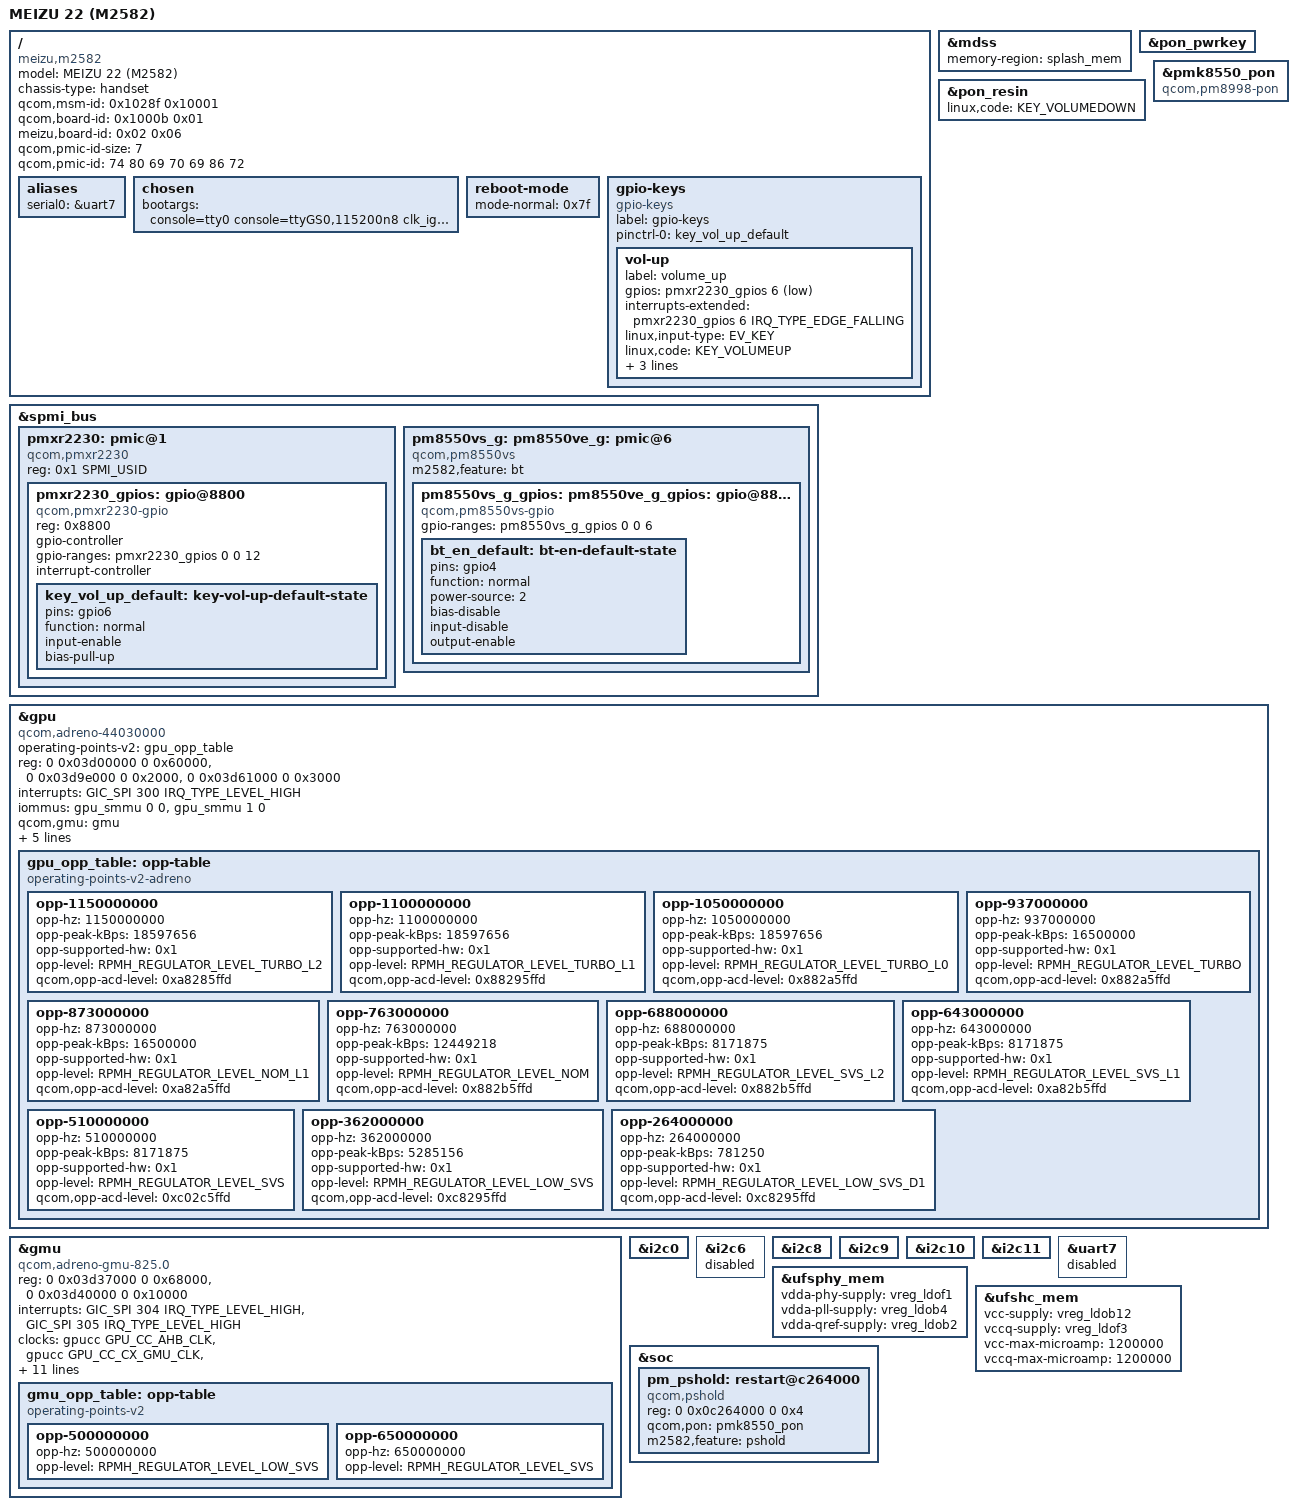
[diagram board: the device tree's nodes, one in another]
// SPDX-License-Identifier: BSD-3-Clause
/dts-v1/;
#include <dt-bindings/input/linux-event-codes.h>
#include "tuna.dtsi"
#include "meizu-m2582-memory.dtsi"
#include "meizu-m2582-power.dtsi"
#include "meizu-m2582-regulators.dtsi"
#include "tuna-display.dtsi"
#include "tuna-usb.dtsi"
#include "tuna-i2c.dtsi"
#include "meizu-m2582-i2c.dtsi"
#include "meizu-m2582-touch.dtsi"
#include "meizu-m2582-wcn-power.dtsi"
#include "meizu-m2582-bt.dtsi"
#include "meizu-m2582-adsp.dtsi"
#include "meizu-m2582-pcie.dtsi"
#include "meizu-m2582-dp.dtsi"
#include "meizu-m2582-audio.dtsi"

&mdss {
	memory-region = <&splash_mem>;
};

/*
 * The PMK8550 sits on the SPMI bus declared in tuna.dtsi. This brings in the
 * PMIC node, its SDAM2 (whose restart-reason field the bootloader reads to pick
 * between Linux and fastboot) and the nvmem-reboot-mode node that writes it.
 *
 * It also adds the PMIC's PON, RTC, GPIO and PWM blocks. PON and PWM are
 * status = "disabled" upstream, and none of the four needs an RPMh regulator,
 * so this deliberately stays clear of the RPMh path that hangs this board.
 */
#include "pmk8550.dtsi"
/* 需要 &pmk8550 标签，必须放在 pmk8550.dtsi 之后 */
#include "meizu-m2582-vadc.dtsi"
/* PMIC GPIO and thermal nodes are separate from the RPMh regulator providers. */
#include "sm8750-pmics.dtsi"
#include "pmd8028.dtsi"
#include "meizu-m2582-amoled.dtsi"
/* 需要 &spmi_bus 标签，必须放在 sm8750-pmics.dtsi 之后 */
#include "meizu-m2582-thermal.dtsi"

/ {
	/*
	 * ASCII only, deliberately: the em dash this used to contain is legal in
	 * a device tree and dtc takes it, but dtschema's decoder rejects the DTB
	 * before any validation runs ("Could not decode node / property model
	 * ... UnicodeDecodeError: 'ascii' codec can't decode byte 0xe2"), so
	 * every make dtbs_check run on this board died at the root node and
	 * looked like a tooling problem rather than a board one.
	 */
	model = "MEIZU 22 (M2582)";
	compatible = "meizu,m2582", "qcom,tuna";
	chassis-type = "handset";
	/* Live socinfo: SM8735 1.1, foundry 1, QRD platform 1.0. */
	qcom,msm-id = <0x1028f 0x10001>;
	qcom,board-id = <0x1000b 0x01>;
	/* ro.boot.proj_version=2, ro.boot.hw_version=6. */
	meizu,board-id = <0x02 0x06>;
	/* Live SMEM PMIC model order, no invented unused slots/revisions. */
	qcom,pmic-id-size = <7>;
	qcom,pmic-id = <74 80 69 70 69 86 72>;
	aliases { serial0 = &uart7; };
	chosen {
		bootargs = "console=tty0 console=ttyGS0,115200n8 clk_ignore_unused pd_ignore_unused cpuidle.off=1 rdinit=/init";
	};
};
/*
 * A nonzero normal reboot reason clears a retained fastboot request.
 * The seven-bit SDAM field uses 0x7f, which ABL treats as a normal boot.
 */
/ {
	reboot-mode {
		mode-normal = <0x7f>;
	};
};

/* PMK8550 PON inputs provide KEY_POWER and volume-down events. */
&pon_pwrkey {
	status = "okay";
};

&pon_resin {
	status = "okay";
	/*
	 * pmk8550.dtsi leaves the key code unset, so the driver's default is used
	 * and volume-down reports KEY_POWER, exactly like the power button. The
	 * factory tree gives it 114 (KEY_VOLUMEDOWN); measured on the board, the
	 * key does deliver events, it just delivered the wrong code.
	 */
	linux,code = <KEY_VOLUMEDOWN>;
};

/* Volume-up is active-low on PMXR2230 GPIO6; the other buttons use PMK8550 PON. */
&spmi_bus {
	pmxr2230: pmic@1 {
		compatible = "qcom,pmxr2230", "qcom,spmi-pmic";
		reg = <0x1 SPMI_USID>;
		#address-cells = <1>;
		#size-cells = <0>;

		pmxr2230_gpios: gpio@8800 {
			compatible = "qcom,pmxr2230-gpio", "qcom,spmi-gpio";
			reg = <0x8800>;
			gpio-controller;
			gpio-ranges = <&pmxr2230_gpios 0 0 12>;
			#gpio-cells = <2>;
			interrupt-controller;
			#interrupt-cells = <2>;
		};
	};
};

&pmxr2230_gpios {
	/*
	 * Measured on the board: `in high normal vin-1 pull-up 30uA`, which is
	 * exactly what the button needs -- idle high, pulled low when pressed,
	 * matching GPIO_ACTIVE_LOW below.
	 *
	 * The factory tree also sets power-source = <1> on this pad. It is left
	 * out: the level reads correctly on the default supply, and adding it
	 * changed nothing measurable.
	 */
	key_vol_up_default: key-vol-up-default-state {
		pins = "gpio6";
		function = "normal";
		input-enable;
		bias-pull-up;
	};
};

/ {
	gpio-keys {
		compatible = "gpio-keys";
		label = "gpio-keys";

		pinctrl-names = "default";
		pinctrl-0 = <&key_vol_up_default>;

		vol-up {
			label = "volume_up";
			gpios = <&pmxr2230_gpios 6 GPIO_ACTIVE_LOW>;
			/*
			 * gpio-keys reads the level through gpiod and would take the
			 * interrupt from gpiod_to_irq() by default. Naming it here
			 * pins it to the pad's own interrupt rather than to whatever
			 * translation that call performs; on this PMIC GPIO the two
			 * turn out to be the same line ("spmi-gpio", irq 141), so
			 * this is belt and braces rather than a fix.
			 */
			interrupts-extended = <&pmxr2230_gpios 6 IRQ_TYPE_EDGE_FALLING>;
			linux,input-type = <EV_KEY>;
			linux,code = <KEY_VOLUMEUP>;
			gpio-key,wakeup;
			debounce-interval = <15>;
			linux,can-disable;
		};
	};
};

/*
 * Use the factory PON compatible and register names; the driver resolves
 * its two windows by name. The key children are inherited from pmk8550.dtsi.
 */
&pmk8550_pon {
	compatible = "qcom,pm8998-pon";
	reg-names = "pon_hlos", "pon_pbs";
};



/*
 * Unused GENI engines remain disabled. Some register windows in wrap1
 * are inaccessible to the application processor and abort on access.
 */

/*
 * Adreno 825 (chip id 0x44030000; the vendor calls it
 * "qcom,adreno-gpu-gen8-6-0").  The first compatible must carry the chip id as
 * eight hex digits, or find_chipid() falls back to the legacy qcom,chipid path
 * and adreno_info() returns NULL -- the only symptom is "no GPU device was
 * found".  Register windows are the vendor's, collapsed to the three mainline
 * consumes (the GPU block covers RSCC at +0x50000); qcom,gmu is mandatory.
 */
&gpu {
	compatible = "qcom,adreno-44030000", "qcom,adreno";
	/*
	 * The vendor node declares no vdd/vddcx either, so the two "supply not
	 * found, using dummy regulator" lines are normal: the vendor GMU's power
	 * domains are the three on &gmu, and the GPU core is parented through the
	 * GMU rather than declaring a rail of its own.
	 */
	status = "okay";

	operating-points-v2 = <&gpu_opp_table>;

	/*
	 * msm_devfreq_init() calls of_devfreq_cooling_register() on this node and
	 * fails without #cooling-cells; the vendor's live tree has it too and uses
	 * the GPU as a cooling device in its gpu-0..gpu-5 thermal zones.
	 */
	#cooling-cells = <2>;

	/*
	 * The first window must cover the RSCC block: a8xx has no separate "rscc"
	 * reg, a6xx_gmu_init() takes gmu->rscc = gpu->mmio + 0x50000, and
	 * a6xx_gmu_rpmh_off() polls TCS8 at byte 0x2228.  At 0x52000 that read fell
	 * past the mapping during the runtime suspend that follows bring-up; 0x60000
	 * is the vendor's own RSCC block size.
	 */
	reg = <0 0x03d00000 0 0x60000>,
	      <0 0x03d9e000 0 0x2000>,
	      <0 0x03d61000 0 0x3000>;
	reg-names = "kgsl_3d0_reg_memory",
		    "cx_mem",
		    "cx_dbgc";

	interrupts = <GIC_SPI 300 IRQ_TYPE_LEVEL_HIGH>;

	iommus = <&gpu_smmu 0 0>,
		 <&gpu_smmu 1 0>;

	qcom,gmu = <&gmu>;

	/*
	 * Speed bin, read from the QFPROM cell the vendor's tuna.dtsi names
	 * gpu_speed_bin (0x138, 9 bits).  Adreno reads it through
	 * adreno_read_speedbin() and filters the OPP table by
	 * opp-supported-hw; none of the levels carry that property yet, so
	 * today this only gets the fuse read and logged -- which is the point
	 * of the first step: learn which bin this die is before changing what
	 * the table advertises.
	 */
	nvmem-cells = <&gpu_speed_bin>;
	nvmem-cell-names = "speed_bin";

	/*
	 * The OPP bandwidth vote follows the factory GFX3D-to-EBI path and
	 * aggregates with the GMU firmware vote.
	 */
	interconnects = <&gem_noc MASTER_GFX3D QCOM_ICC_TAG_ALWAYS
			 &mc_virt SLAVE_EBI1 QCOM_ICC_TAG_ALWAYS>;
	interconnect-names = "gpu_icc_path";

	/*
	 * GPU frequencies, RPMh corners, ACD levels and DDR bandwidth follow
	 * the factory KGSL power levels. Both supported speed bins use bit 0;
	 * opp-supported-hw is required once the speed-bin fuse is readable.
	 */
	gpu_opp_table: opp-table {
		compatible = "operating-points-v2-adreno", "operating-points-v2";

		opp-1150000000 {
			opp-hz = /bits/ 64 <1150000000>;
			opp-peak-kBps = <18597656>;
			opp-supported-hw = <0x1>;
			opp-level = <RPMH_REGULATOR_LEVEL_TURBO_L2>;
			qcom,opp-acd-level = <0xa8285ffd>;
		};

		opp-1100000000 {
			opp-hz = /bits/ 64 <1100000000>;
			opp-peak-kBps = <18597656>;
			opp-supported-hw = <0x1>;
			opp-level = <RPMH_REGULATOR_LEVEL_TURBO_L1>;
			qcom,opp-acd-level = <0x88295ffd>;
		};

		opp-1050000000 {
			opp-hz = /bits/ 64 <1050000000>;
			opp-peak-kBps = <18597656>;
			opp-supported-hw = <0x1>;
			opp-level = <RPMH_REGULATOR_LEVEL_TURBO_L0>;
			qcom,opp-acd-level = <0x882a5ffd>;
		};

		opp-937000000 {
			opp-hz = /bits/ 64 <937000000>;
			opp-peak-kBps = <16500000>;
			opp-supported-hw = <0x1>;
			opp-level = <RPMH_REGULATOR_LEVEL_TURBO>;
			qcom,opp-acd-level = <0x882a5ffd>;
		};

		opp-873000000 {
			opp-hz = /bits/ 64 <873000000>;
			opp-peak-kBps = <16500000>;
			opp-supported-hw = <0x1>;
			opp-level = <RPMH_REGULATOR_LEVEL_NOM_L1>;
			qcom,opp-acd-level = <0xa82a5ffd>;
		};

		opp-763000000 {
			opp-hz = /bits/ 64 <763000000>;
			opp-peak-kBps = <12449218>;
			opp-supported-hw = <0x1>;
			opp-level = <RPMH_REGULATOR_LEVEL_NOM>;
			qcom,opp-acd-level = <0x882b5ffd>;
		};

		opp-688000000 {
			opp-hz = /bits/ 64 <688000000>;
			opp-peak-kBps = <8171875>;
			opp-supported-hw = <0x1>;
			opp-level = <RPMH_REGULATOR_LEVEL_SVS_L2>;
			qcom,opp-acd-level = <0x882b5ffd>;
		};

		opp-643000000 {
			opp-hz = /bits/ 64 <643000000>;
			opp-peak-kBps = <8171875>;
			opp-supported-hw = <0x1>;
			opp-level = <RPMH_REGULATOR_LEVEL_SVS_L1>;
			qcom,opp-acd-level = <0xa82b5ffd>;
		};

		opp-510000000 {
			opp-hz = /bits/ 64 <510000000>;
			opp-peak-kBps = <8171875>;
			opp-supported-hw = <0x1>;
			opp-level = <RPMH_REGULATOR_LEVEL_SVS>;
			qcom,opp-acd-level = <0xc02c5ffd>;
		};

		opp-362000000 {
			opp-hz = /bits/ 64 <362000000>;
			opp-peak-kBps = <5285156>;
			opp-supported-hw = <0x1>;
			opp-level = <RPMH_REGULATOR_LEVEL_LOW_SVS>;
			qcom,opp-acd-level = <0xc8295ffd>;
		};

		opp-264000000 {
			opp-hz = /bits/ 64 <264000000>;
			opp-peak-kBps = <781250>;
			opp-supported-hw = <0x1>;
			opp-level = <RPMH_REGULATOR_LEVEL_LOW_SVS_D1>;
			qcom,opp-acd-level = <0xc8295ffd>;
		};
	};
};

/*
 * The GMU is a sibling of the GPU node, not a child: the vendor tree has it
 * at 0x3d37000 and mainline finds it through the GPU's qcom,gmu phandle.
 * reg index 0 is the base a6xx_gmu_get_mmio() maps; RSCC comes from the GPU
 * window (see &gpu).  Power domains are "cx", "gmu", "gx" in that order,
 * matching gpu_cc_cx_gdsc, gpu_cc_cx_gmu_gdsc and gx_clkctl_gx_gdsc.
 */
&gmu {
	compatible = "qcom,adreno-gmu-825.0", "qcom,adreno-gmu";
	status = "okay";

	/*
	 * The "gmu_pdc" region is deliberately not declared: with it present
	 * a6xx_gmu_rpmh_init() writes the GPU's PDC at probe (0x4520 = 0,
	 * 0x4500 = 0x80000001) and the boot hangs right after the HFI
	 * handshake.  The a8xx branch handles the region being absent.
	 */
	reg = <0 0x03d37000 0 0x68000>,
	      <0 0x03d40000 0 0x10000>;
	reg-names = "gmu", "gmu_ao_blk_dec0";

	interrupts = <GIC_SPI 304 IRQ_TYPE_LEVEL_HIGH>,
		     <GIC_SPI 305 IRQ_TYPE_LEVEL_HIGH>;
	interrupt-names = "hfi", "gmu";

	/*
	 * "axi" is GCC_DDRSS_GPU_AXI_CLK, which the vendor's GMU node and
	 * sm8650 carry: without it the GMU cannot reach the bus, so firmware
	 * loads but the M3 never reports back.
	 */
	clocks = <&gpucc GPU_CC_AHB_CLK>,
		 <&gpucc GPU_CC_CX_GMU_CLK>,
		 <&gpucc GPU_CC_CXO_CLK>,
		 <&gcc GCC_DDRSS_GPU_AXI_CLK>,
		 <&gcc GCC_GPU_GEMNOC_GFX_CLK>,
		 <&gpucc GPU_CC_HUB_CX_INT_CLK>,
		 <&gpucc GPU_CC_DEMET_CLK>;
	clock-names = "ahb", "gmu", "cxo", "axi", "memnoc", "hub", "demet";

	/*
	 * Three domains, as the vendor's GMU node declares: "cx", "gmu_cx", "gx".
	 * a6xx_gmu_init() resolves "gx" by name and mainline's a8xx power-up path is
	 * built on it (a6xx_gmu_fw_start -> a6xx_gmu_gxpd_get raises the GX rail
	 * before the GMU is started); with only two domains gmu->gxpd stayed NULL.
	 */
	/*
	 * No RPMh rails (cx.lvl, mx.lvl) here: a6xx_gmu_init() asks only for
	 * "cx" and "gx" by name, and declaring them makes the boot hang.  The
	 * vendor's gen8_gmu_boot holds the CX rail across the whole power cycle
	 * (kgsl_pwrctrl_enable_cx_gdsc .. disable_cx_gdsc), which is where they
	 * belong -- the .supply = "vdd_cx" work.
	 */
	power-domains = <&gpucc GPU_CC_CX_GDSC>,
			<&gpucc GPU_CC_CX_GMU_GDSC>,
			<&gxclkctl GX_CLKCTL_GX_GDSC>;
	power-domain-names = "cx", "gmu", "gx";

	/*
	 * Required, not optional: a6xx_gmu_acd_probe() sends the GPU's ACD state
	 * to AOSS over this and returns -EINVAL if it is missing while the OPP
	 * table carries qcom,opp-acd-level. The vendor's GMU node has the same
	 * property, and sends the ACD state first thing in gen8_gmu_first_boot.
	 */
	qcom,qmp = <&aoss_qmp>;

	iommus = <&gpu_smmu 5 0>;

	operating-points-v2 = <&gmu_opp_table>;

	/*
	 * a6xx_gmu_pwrlevels_probe() requires this table.  Frequencies and levels
	 * are the vendor's qcom,gmu-freq-table <0x1dcd6500 0x40 0x26be3680 0x80>:
	 * 500 MHz at LOW_SVS and 650 MHz at SVS.
	 */
	gmu_opp_table: opp-table {
		compatible = "operating-points-v2";

		opp-500000000 {
			opp-hz = /bits/ 64 <500000000>;
			opp-level = <RPMH_REGULATOR_LEVEL_LOW_SVS>;
		};

		opp-650000000 {
			opp-hz = /bits/ 64 <650000000>;
			opp-level = <RPMH_REGULATOR_LEVEL_SVS>;
		};
	};
};

&i2c0 { status = "okay"; };

/* SE6 stays disabled: enabling it panics the board, see above. */
&i2c6 { status = "disabled"; };

/*
 * The four buses that carry the board's I2C devices, from the vendor overlay
 * (see meizu-m2582-i2c.dtsi for how that overlay was identified and why every
 * constant in it could be cross-checked). Brought up one step at a time: the
 * controllers first, with no child devices declared, so a probe failure is
 * attributable to the bus and nothing above it. The devices follow once each
 * address has been seen answering on the wire.
 */
&i2c8 { status = "okay"; };
&i2c9 { status = "okay"; };
&i2c10 { status = "okay"; };
&i2c11 { status = "okay"; };

/* Ordinary USB cable diagnostics: keep the unconnected UART disabled. */

&uart7 { status = "disabled"; };
&ufsphy_mem {
	vdda-phy-supply = <&vreg_ldof1>;
	vdda-pll-supply = <&vreg_ldob4>;
	vdda-qref-supply = <&vreg_ldob2>;
	status = "okay";
};
&ufshc_mem {
	vcc-supply = <&vreg_ldob12>;
	vccq-supply = <&vreg_ldof3>;
	vcc-max-microamp = <1200000>;
	vccq-max-microamp = <1200000>;
	status = "okay";
};

/*
 * The AP cannot write the PMIC RTC counter. SDAM offset writes lose
 * the low 16 bits on this board, so m2582-clock keeps the offset on
 * the root filesystem. The counter continues across power-off.
 */
/*
 * USID 6 is PM8550VS, with six GPIOs, overriding the PM8550VE node
 * in the shared PMIC include. Bluetooth enable uses this VS instance.
 */
&spmi_bus {
	pm8550vs_g: pm8550ve_g: pmic@6 {
		compatible = "qcom,pm8550vs", "qcom,spmi-pmic";

		/*
		 * The factory tree says this instance is a PM8550VS (its
		 * pinctrl node is qcom,pm8550vs-gpio with six lines, and its
		 * pmic-ecid names it pm8550vs_g), while the SoC file it
		 * overrides assumed a PM8550VE with eight.  Leaving that node
		 * in place puts two gpio drivers on one SPMI block, so it is
		 * switched off here rather than left to race.
		 */
		status = "okay";

		/* Its only consumer is the Bluetooth enable line. */
		m2582,feature = "bt";

		pm8550vs_g_gpios: pm8550ve_g_gpios: gpio@8800 {
			compatible = "qcom,pm8550vs-gpio", "qcom,spmi-gpio";
			gpio-ranges = <&pm8550vs_g_gpios 0 0 6>;

			/*
			 * The factory enables the GPIO output driver through pinctrl;
			 * changing its value alone does not enable the pad.
			 */
			bt_en_default: bt-en-default-state {
				pins = "gpio4";
				function = "normal";
				power-source = <2>;
				bias-disable;
				input-disable;
				output-enable;
			};
		};

	};
};

/*
 * Program the PMIC PBS for a hard reset before releasing PS_HOLD.
 * The panel needs this power cycle to recover reliably after reboot.
 */
&soc {
	/* Read-only LLCC identification for the optional display diagnostic. */
	pm_pshold: restart@c264000 {
		compatible = "qcom,pshold";
		reg = <0 0x0c264000 0 0x4>;
		qcom,pon = <&pmk8550_pon>;
		m2582,feature = "pshold";
	};
};
